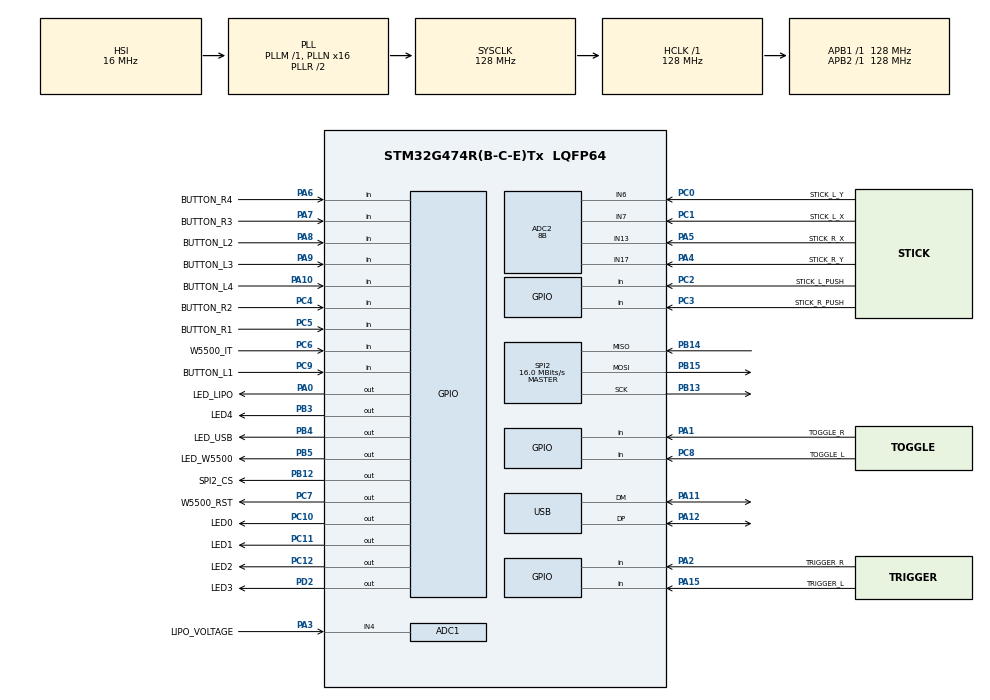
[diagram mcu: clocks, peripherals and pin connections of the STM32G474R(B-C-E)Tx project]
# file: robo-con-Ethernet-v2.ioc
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ADC1.Channel-0\#ChannelRegularConversion=ADC_CHANNEL_4
ADC1.ClockPrescaler=ADC_CLOCK_SYNC_PCLK_DIV4
ADC1.ContinuousConvMode=ENABLE
ADC1.DMAContinuousRequests=ENABLE
ADC1.NbrOfConversion=1
ADC1.NbrOfConversionFlag=1
ADC1.OffsetNumber-0\#ChannelRegularConversion=ADC_OFFSET_NONE
ADC1.Overrun=ADC_OVR_DATA_OVERWRITTEN
ADC1.OversamplingMode=DISABLE
ADC1.Rank-0\#ChannelRegularConversion=1
ADC1.Resolution=ADC_RESOLUTION_12B
ADC1.SamplingTime-0\#ChannelRegularConversion=ADC_SAMPLETIME_640CYCLES_5
ADC1.master=1
ADC2.Channel-0\#ChannelRegularConversion=ADC_CHANNEL_13
ADC2.Channel-1\#ChannelRegularConversion=ADC_CHANNEL_17
ADC2.Channel-2\#ChannelRegularConversion=ADC_CHANNEL_7
ADC2.Channel-3\#ChannelRegularConversion=ADC_CHANNEL_6
ADC2.ContinuousConvMode=ENABLE
ADC2.DMAContinuousRequests=ENABLE
ADC2.NbrOfConversion=4
ADC2.NbrOfConversionFlag=1
ADC2.OffsetNumber-0\#ChannelRegularConversion=ADC_OFFSET_NONE
ADC2.OffsetNumber-1\#ChannelRegularConversion=ADC_OFFSET_NONE
ADC2.OffsetNumber-2\#ChannelRegularConversion=ADC_OFFSET_NONE
ADC2.OffsetNumber-3\#ChannelRegularConversion=ADC_OFFSET_NONE
ADC2.Overrun=ADC_OVR_DATA_OVERWRITTEN
ADC2.Rank-0\#ChannelRegularConversion=1
ADC2.Rank-1\#ChannelRegularConversion=2
ADC2.Rank-2\#ChannelRegularConversion=3
ADC2.Rank-3\#ChannelRegularConversion=4
ADC2.Resolution=ADC_RESOLUTION_8B
ADC2.SamplingTime-0\#ChannelRegularConversion=ADC_SAMPLETIME_47CYCLES_5
ADC2.SamplingTime-1\#ChannelRegularConversion=ADC_SAMPLETIME_47CYCLES_5
ADC2.SamplingTime-2\#ChannelRegularConversion=ADC_SAMPLETIME_47CYCLES_5
ADC2.SamplingTime-3\#ChannelRegularConversion=ADC_SAMPLETIME_47CYCLES_5
Dma.ADC1.0.Direction=DMA_PERIPH_TO_MEMORY
Dma.ADC1.0.EventEnable=DISABLE
Dma.ADC1.0.Instance=DMA1_Channel1
Dma.ADC1.0.MemDataAlignment=DMA_MDATAALIGN_HALFWORD
Dma.ADC1.0.MemInc=DMA_MINC_ENABLE
Dma.ADC1.0.Mode=DMA_CIRCULAR
Dma.ADC1.0.PeriphDataAlignment=DMA_PDATAALIGN_HALFWORD
Dma.ADC1.0.PeriphInc=DMA_PINC_DISABLE
Dma.ADC1.0.Polarity=HAL_DMAMUX_REQ_GEN_RISING
Dma.ADC1.0.Priority=DMA_PRIORITY_LOW
Dma.ADC1.0.RequestNumber=1
Dma.ADC1.0.SignalID=NONE
Dma.ADC1.0.SyncEnable=DISABLE
Dma.ADC1.0.SyncPolarity=HAL_DMAMUX_SYNC_NO_EVENT
Dma.ADC1.0.SyncRequestNumber=1
Dma.ADC1.0.SyncSignalID=NONE
Dma.ADC2.1.Direction=DMA_PERIPH_TO_MEMORY
Dma.ADC2.1.EventEnable=DISABLE
Dma.ADC2.1.Instance=DMA1_Channel2
Dma.ADC2.1.MemDataAlignment=DMA_MDATAALIGN_HALFWORD
Dma.ADC2.1.MemInc=DMA_MINC_ENABLE
Dma.ADC2.1.Mode=DMA_CIRCULAR
Dma.ADC2.1.PeriphDataAlignment=DMA_PDATAALIGN_HALFWORD
Dma.ADC2.1.PeriphInc=DMA_PINC_DISABLE
Dma.ADC2.1.Polarity=HAL_DMAMUX_REQ_GEN_RISING
Dma.ADC2.1.Priority=DMA_PRIORITY_LOW
Dma.ADC2.1.RequestNumber=1
Dma.ADC2.1.SignalID=NONE
Dma.ADC2.1.SyncEnable=DISABLE
Dma.ADC2.1.SyncPolarity=HAL_DMAMUX_SYNC_NO_EVENT
Dma.ADC2.1.SyncRequestNumber=1
Dma.ADC2.1.SyncSignalID=NONE
Dma.Request0=ADC1
Dma.Request1=ADC2
Mcu.Family=STM32G4
Mcu.Name=STM32G474R(B-C-E)Tx
Mcu.Package=LQFP64
NVIC.DMA1_Channel1_IRQn=true\:4\:0\:true\:false\:true\:false\:true\:true
NVIC.DMA1_Channel2_IRQn=true\:0\:0\:false\:false\:true\:false\:true\:true
NVIC.PriorityGroup=NVIC_PRIORITYGROUP_4
NVIC.TIM6_DAC_IRQn=true\:2\:0\:true\:false\:true\:true\:true\:true
NVIC.USB_HP_IRQn=true\:6\:0\:true\:false\:true\:true\:true\:true
NVIC.USB_LP_IRQn=true\:7\:0\:true\:false\:true\:true\:true\:true
PA0.GPIO_Label=LED_LIPO
PA0.Signal=GPIO_Output
PA1.GPIO_Label=TOGGLE_R
PA1.Signal=GPIO_Input
PA10.GPIO_Label=BUTTON_L4
PA10.GPIO_PuPd=GPIO_PULLDOWN
PA10.Signal=GPIO_Input
PA11.Mode=Device
PA11.Signal=USB_DM
PA12.Mode=Device
PA12.Signal=USB_DP
PA13.Mode=Serial_Wire
PA13.Signal=SYS_JTMS-SWDIO
PA14.Mode=Serial_Wire
PA14.Signal=SYS_JTCK-SWCLK
PA15.GPIO_Label=TRIGGER_L
PA15.GPIO_PuPd=GPIO_PULLDOWN
PA15.Signal=GPIO_Input
PA2.GPIO_Label=TRIGGER_R
PA2.GPIO_PuPd=GPIO_PULLDOWN
PA2.Signal=GPIO_Input
PA3.GPIO_Label=LIPO_VOLTAGE
PA3.Mode=IN4-Single-Ended
PA3.Signal=ADC1_IN4
PA4.GPIO_Label=STICK_R_Y
PA4.Mode=IN17-Single-Ended
PA4.Signal=ADC2_IN17
PA5.GPIO_Label=STICK_R_X
PA5.Mode=IN13-Single-Ended
PA5.Signal=ADC2_IN13
PA6.GPIO_Label=BUTTON_R4
PA6.GPIO_PuPd=GPIO_PULLDOWN
PA6.Signal=GPIO_Input
PA7.GPIO_Label=BUTTON_R3
PA7.GPIO_PuPd=GPIO_PULLDOWN
PA7.Signal=GPIO_Input
PA8.GPIO_Label=BUTTON_L2
PA8.GPIO_PuPd=GPIO_PULLDOWN
PA8.Signal=GPIO_Input
PA9.GPIO_Label=BUTTON_L3
PA9.GPIO_PuPd=GPIO_PULLDOWN
PA9.Signal=GPIO_Input
PB12.GPIO_Label=SPI2_CS
PB12.GPIO_Speed=GPIO_SPEED_FREQ_MEDIUM
PB12.Signal=GPIO_Output
PB13.Mode=Full_Duplex_Master
PB13.Signal=SPI2_SCK
PB14.Mode=Full_Duplex_Master
PB14.Signal=SPI2_MISO
PB15.Mode=Full_Duplex_Master
PB15.Signal=SPI2_MOSI
PB3.GPIO_Label=LED4
PB3.Signal=GPIO_Output
PB4.GPIO_Label=LED_USB
PB4.Signal=GPIO_Output
PB5.GPIO_Label=LED_W5500
PB5.Signal=GPIO_Output
PC0.GPIO_Label=STICK_L_Y
PC0.Mode=IN6-Single-Ended
PC0.Signal=ADC2_IN6
PC1.GPIO_Label=STICK_L_X
PC1.Mode=IN7-Single-Ended
PC1.Signal=ADC2_IN7
PC10.GPIO_Label=LED0
PC10.Signal=GPIO_Output
PC11.GPIO_Label=LED1
PC11.Signal=GPIO_Output
PC12.GPIO_Label=LED2
PC12.Signal=GPIO_Output
PC2.GPIO_Label=STICK_L_PUSH
PC2.GPIO_PuPd=GPIO_PULLDOWN
PC2.Signal=GPIO_Input
PC3.GPIO_Label=STICK_R_PUSH
PC3.GPIO_PuPd=GPIO_PULLDOWN
PC3.Signal=GPIO_Input
PC4.GPIO_Label=BUTTON_R2
PC4.GPIO_PuPd=GPIO_PULLDOWN
PC4.Signal=GPIO_Input
PC5.GPIO_Label=BUTTON_R1
PC5.GPIO_PuPd=GPIO_PULLDOWN
PC5.Signal=GPIO_Input
PC6.GPIO_Label=W5500_IT
PC6.Signal=GPIO_Input
PC7.GPIO_Label=W5500_RST
PC7.Signal=GPIO_Output
PC8.GPIO_Label=TOGGLE_L
PC8.Signal=GPIO_Input
PC9.GPIO_Label=BUTTON_L1
PC9.GPIO_PuPd=GPIO_PULLDOWN
PC9.Signal=GPIO_Input
PD2.GPIO_Label=LED3
PD2.Signal=GPIO_Output
ProjectManager.HeapSize=0x200
ProjectManager.StackSize=0x400
ProjectManager.TargetToolchain=CMake
RCC.ADC12Freq_Value=128000000
RCC.ADC345Freq_Value=128000000
RCC.AHBFreq_Value=128000000
RCC.APB1Freq_Value=128000000
RCC.APB1TimFreq_Value=128000000
RCC.APB2Freq_Value=128000000
RCC.APB2TimFreq_Value=128000000
RCC.CK48CLockSelection=RCC_USBCLKSOURCE_HSI48
RCC.CortexFreq_Value=128000000
RCC.EXTERNAL_CLOCK_VALUE=12288000
RCC.HCLKFreq_Value=128000000
RCC.HSE_VALUE=8000000
RCC.HSI48_VALUE=48000000
RCC.HSI_VALUE=16000000
RCC.LSE_VALUE=32768
RCC.PLLN=16
RCC.SYSCLKFreq_VALUE=128000000
RCC.SYSCLKSource=RCC_SYSCLKSOURCE_PLLCLK
RCC.USART1CLockSelection=RCC_USART1CLKSOURCE_HSI
RCC.USBFreq_Value=48000000
RCC.VCOOutputFreq_Value=256000000
SPI2.BaudRatePrescaler=SPI_BAUDRATEPRESCALER_8
SPI2.CalculateBaudRate=16.0 MBits/s
SPI2.DataSize=SPI_DATASIZE_8BIT
SPI2.Direction=SPI_DIRECTION_2LINES
SPI2.Mode=SPI_MODE_MASTER
SPI2.VirtualType=VM_MASTER
TIM6.PeriodNoDither=9999
TIM6.Prescaler=127
USB_DEVICE.CLASS_NAME_FS=CDC
USB_DEVICE.VirtualMode=Cdc
USB_DEVICE.VirtualModeFS=Cdc_FS
VP_ADC1_TempSens_Input.Mode=IN-TempSens
VP_SYS_VS_DBSignals.Mode=DisableDeadBatterySignals
VP_TIM6_VS_ClockSourceINT.Mode=Enable_Timer
VP_USB_DEVICE_VS_USB_DEVICE_CDC_FS.Mode=CDC_FS
board=custom

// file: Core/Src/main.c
/* USER CODE BEGIN Header */
/**
 ******************************************************************************
 * @file           : main.c
 * @brief          : Main program body
 ******************************************************************************
 * @attention
 *
 * Copyright (c) 2026 STMicroelectronics.
 * All rights reserved.
 *
 * This software is licensed under terms that can be found in the LICENSE file
 * in the root directory of this software component.
 * If no LICENSE file comes with this software, it is provided AS-IS.
 *
 ******************************************************************************
 */
/* USER CODE END Header */
#include "main.h"

#include "adc.h"
#include "dma.h"
#include "gpio.h"
#include "spi.h"
#include "tim.h"
#include "usb_device.h"

/* USER CODE BEGIN Includes */
#include "app/app.hpp"
#include "usbd_cdc_if.h"
/* USER CODE END Includes */

void SystemClock_Config(void);

/* USER CODE BEGIN 0 */
int _write(int file, char* ptr, int len)
{
    if ((CDC_Transmit_FS((uint8_t*)ptr, len) != USBD_OK)) return 0;
    return len;
}
/* USER CODE END 0 */

int main(void)
{

    /* MCU Configuration--------------------------------------------------------*/

    /* Reset of all peripherals, Initializes the Flash interface and the Systick. */
    HAL_Init();

    /* Configure the system clock */
    SystemClock_Config();

    /* Initialize all configured peripherals */
    MX_GPIO_Init();
    MX_DMA_Init();
    MX_ADC1_Init();
    MX_TIM6_Init();
    MX_USB_Device_Init();
    MX_ADC2_Init();
    MX_SPI2_Init();
    /* USER CODE BEGIN 2 */
    setup();
    /* USER CODE END 2 */

    /* Infinite loop */
    while (1) {

        /* USER CODE BEGIN 3 */
        loop();
    }
    /* USER CODE END 3 */
}

void SystemClock_Config(void)
{
    RCC_OscInitTypeDef RCC_OscInitStruct = {0};
    RCC_ClkInitTypeDef RCC_ClkInitStruct = {0};

    /** Configure the main internal regulator output voltage
     */
    HAL_PWREx_ControlVoltageScaling(PWR_REGULATOR_VOLTAGE_SCALE1);

    /** Initializes the RCC Oscillators according to the specified parameters
     * in the RCC_OscInitTypeDef structure.
     */
    RCC_OscInitStruct.OscillatorType      = RCC_OSCILLATORTYPE_HSI | RCC_OSCILLATORTYPE_HSI48;
    RCC_OscInitStruct.HSIState            = RCC_HSI_ON;
    RCC_OscInitStruct.HSICalibrationValue = RCC_HSICALIBRATION_DEFAULT;
    RCC_OscInitStruct.HSI48State          = RCC_HSI48_ON;
    RCC_OscInitStruct.PLL.PLLState        = RCC_PLL_ON;
    RCC_OscInitStruct.PLL.PLLSource       = RCC_PLLSOURCE_HSI;
    RCC_OscInitStruct.PLL.PLLM            = RCC_PLLM_DIV1;
    RCC_OscInitStruct.PLL.PLLN            = 16;
    RCC_OscInitStruct.PLL.PLLP            = RCC_PLLP_DIV2;
    RCC_OscInitStruct.PLL.PLLQ            = RCC_PLLQ_DIV2;
    RCC_OscInitStruct.PLL.PLLR            = RCC_PLLR_DIV2;
    if (HAL_RCC_OscConfig(&RCC_OscInitStruct) != HAL_OK) {
        Error_Handler();
    }

    /** Initializes the CPU, AHB and APB buses clocks
     */
    RCC_ClkInitStruct.ClockType =
        RCC_CLOCKTYPE_HCLK | RCC_CLOCKTYPE_SYSCLK | RCC_CLOCKTYPE_PCLK1 | RCC_CLOCKTYPE_PCLK2;
    RCC_ClkInitStruct.SYSCLKSource   = RCC_SYSCLKSOURCE_PLLCLK;
    RCC_ClkInitStruct.AHBCLKDivider  = RCC_SYSCLK_DIV1;
    RCC_ClkInitStruct.APB1CLKDivider = RCC_HCLK_DIV1;
    RCC_ClkInitStruct.APB2CLKDivider = RCC_HCLK_DIV1;

    if (HAL_RCC_ClockConfig(&RCC_ClkInitStruct, FLASH_LATENCY_4) != HAL_OK) {
        Error_Handler();
    }
}

void Error_Handler(void)
{
    __disable_irq();
    while (1) {
    }
}
